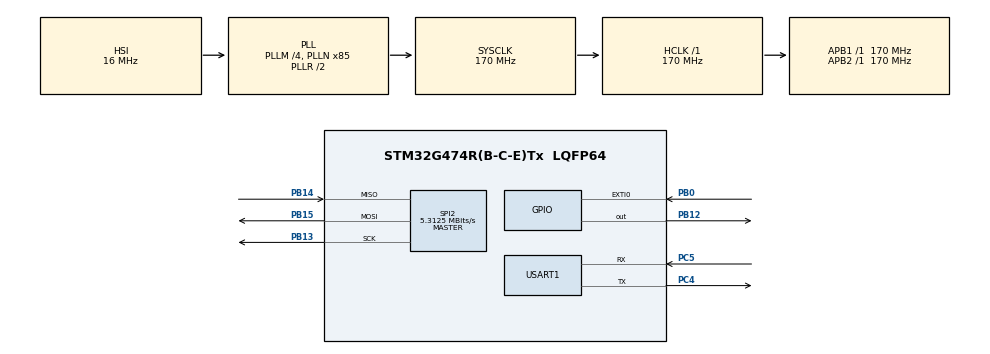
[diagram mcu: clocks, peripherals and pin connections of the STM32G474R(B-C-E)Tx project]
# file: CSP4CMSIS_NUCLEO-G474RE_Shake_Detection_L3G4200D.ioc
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FREERTOS.Tasks01=defaultTask,24,256,StartDefaultTask,Default,NULL,Static,defaultTaskBuffer,defaultTaskControlBlock
FREERTOS.configTOTAL_HEAP_SIZE=1024
FREERTOS.configUSE_NEWLIB_REENTRANT=1
Mcu.Family=STM32G4
Mcu.Name=STM32G474R(B-C-E)Tx
Mcu.Package=LQFP64
NUCLEO-G474RE.BUTTON=1
NUCLEO-G474RE.LD2=true
NUCLEO-G474RE.VCP=true
NVIC.EXTI0_IRQn=true\:5\:0\:false\:false\:true\:true\:true\:true\:true
NVIC.EXTI15_10_IRQn=true\:5\:0\:false\:false\:true\:true\:false\:true\:true
NVIC.PriorityGroup=NVIC_PRIORITYGROUP_4
NVIC.TIM1_UP_TIM16_IRQn=true\:15\:0\:false\:false\:true\:false\:false\:true\:true
NVIC.TimeBase=TIM1_UP_TIM16_IRQn
NVIC.TimeBaseIP=TIM1
PA13.GPIO_Label=T_SWDIO
PA13.Signal=SYS_JTMS-SWDIO
PA14.GPIO_Label=T_SWCLK
PA14.Signal=SYS_JTCK-SWCLK
PA2.Signal=LPUART1_TX
PA3.Signal=LPUART1_RX
PB0.Signal=GPXTI0
PB12.Signal=GPIO_Output
PB13.Mode=Full_Duplex_Master
PB13.Signal=SPI2_SCK
PB14.Mode=Full_Duplex_Master
PB14.Signal=SPI2_MISO
PB15.Mode=Full_Duplex_Master
PB15.Signal=SPI2_MOSI
PB3.GPIO_Label=T_SWO
PB3.Signal=SYS_JTDO-SWO
PC14-OSC32_IN.GPIO_Label=RCC_OSC32_IN
PC14-OSC32_IN.Signal=RCC_OSC32_IN
PC15-OSC32_OUT.GPIO_Label=RCC_OSC32_OUT
PC15-OSC32_OUT.Signal=RCC_OSC32_OUT
PC4.Mode=Asynchronous
PC4.Signal=USART1_TX
PC5.Mode=Asynchronous
PC5.Signal=USART1_RX
PF0-OSC_IN.GPIO_Label=RCC_OSC_IN
PF0-OSC_IN.Signal=RCC_OSC_IN
PF1-OSC_OUT.GPIO_Label=RCC_OSC_OUT
PF1-OSC_OUT.Signal=RCC_OSC_OUT
ProjectManager.HeapSize=0x200
ProjectManager.StackSize=0x400
ProjectManager.TargetToolchain=STM32CubeIDE
RCC.ADC12Freq_Value=170000000
RCC.ADC345Freq_Value=170000000
RCC.AHBFreq_Value=170000000
RCC.APB1Freq_Value=170000000
RCC.APB1TimFreq_Value=170000000
RCC.APB2Freq_Value=170000000
RCC.APB2TimFreq_Value=170000000
RCC.CortexFreq_Value=170000000
RCC.EXTERNAL_CLOCK_VALUE=12288000
RCC.HCLKFreq_Value=170000000
RCC.HSE_VALUE=24000000
RCC.HSI48_VALUE=48000000
RCC.HSI_VALUE=16000000
RCC.LSE_VALUE=32768
RCC.PLLM=RCC_PLLM_DIV4
RCC.PLLN=85
RCC.RTCClockSelection=RCC_RTCCLKSOURCE_LSE
RCC.SYSCLKFreq_VALUE=170000000
RCC.SYSCLKSource=RCC_SYSCLKSOURCE_PLLCLK
RCC.USBFreq_Value=170000000
RCC.VCOOutputFreq_Value=340000000
SPI2.BaudRatePrescaler=SPI_BAUDRATEPRESCALER_32
SPI2.CLKPhase=SPI_PHASE_2EDGE
SPI2.CLKPolarity=SPI_POLARITY_HIGH
SPI2.CalculateBaudRate=5.3125 MBits/s
SPI2.DataSize=SPI_DATASIZE_8BIT
SPI2.Direction=SPI_DIRECTION_2LINES
SPI2.Mode=SPI_MODE_MASTER
SPI2.VirtualType=VM_MASTER
USART1.VirtualMode-Asynchronous=VM_ASYNC
VP_FREERTOS_VS_CMSIS_V2.Mode=CMSIS_V2
VP_NUCLEO-G474RE_VS_BSP_COMMON.Mode=COMMON
VP_SYS_VS_DBSignals.Mode=DisableDeadBatterySignals
VP_SYS_VS_tim1.Mode=TIM1
board=NUCLEO-G474RE

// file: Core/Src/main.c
/* USER CODE BEGIN Header */
/**
  ******************************************************************************
  * @file           : main.c
  * @brief          : Main program body
  ******************************************************************************
  * @attention
  *
  * Copyright (c) 2026 STMicroelectronics.
  * All rights reserved.
  *
  * This software is licensed under terms that can be found in the LICENSE file
  * in the root directory of this software component.
  * If no LICENSE file comes with this software, it is provided AS-IS.
  *
  ******************************************************************************
  */
/* USER CODE END Header */
#include "main.h"
#include "cmsis_os.h"

/* USER CODE BEGIN Includes */
#include "application.h"
#include <stdio.h>
/* USER CODE END Includes */

typedef StaticTask_t osStaticThreadDef_t;

COM_InitTypeDef BspCOMInit;
SPI_HandleTypeDef hspi2;

UART_HandleTypeDef huart1;

void SystemClock_Config(void);
static void MX_GPIO_Init(void);
static void MX_SPI2_Init(void);
static void MX_USART1_UART_Init(void);

int main(void)
{

  /* MCU Configuration--------------------------------------------------------*/

  /* Reset of all peripherals, Initializes the Flash interface and the Systick. */
  HAL_Init();

  /* Configure the system clock */
  SystemClock_Config();

  /* Initialize all configured peripherals */
  MX_GPIO_Init();
  MX_SPI2_Init();
  MX_USART1_UART_Init();
  /* USER CODE BEGIN 2 */
  /* Unbuffered stdout: newlib's printf() would otherwise malloc() a 1 KB stdout buffer on first
     use (measured: 1032 B). With this, nothing in the program allocates heap memory. */
  setvbuf(stdout, NULL, _IONBF, 0);

  /* USER CODE END 2 */

  /* Init scheduler */
  osKernelInitialize();

  /* USER CODE BEGIN RTOS_THREADS */
  /* add threads, ... */
  csp_app_main_init();  /* application.cpp: creates MainApp, which starts the CSP network */
  /* USER CODE END RTOS_THREADS */

  /* Initialize led */
  BSP_LED_Init(LED_GREEN);

  /* Initialize USER push-button, will be used to trigger an interrupt each time it's pressed.*/
  BSP_PB_Init(BUTTON_USER, BUTTON_MODE_EXTI);

  /* Initialize COM1 port (115200, 8 bits (7-bit data + 1 stop bit), no parity */
  BspCOMInit.BaudRate   = 115200;
  BspCOMInit.WordLength = COM_WORDLENGTH_8B;
  BspCOMInit.StopBits   = COM_STOPBITS_1;
  BspCOMInit.Parity     = COM_PARITY_NONE;
  BspCOMInit.HwFlowCtl  = COM_HWCONTROL_NONE;
  if (BSP_COM_Init(COM1, &BspCOMInit) != BSP_ERROR_NONE)
  {
    Error_Handler();
  }

  /* Start scheduler */
  osKernelStart();

  /* We should never get here as control is now taken by the scheduler */

  /* Infinite loop */
  while (1)
  {

  }
}

void SystemClock_Config(void)
{
  RCC_OscInitTypeDef RCC_OscInitStruct = {0};
  RCC_ClkInitTypeDef RCC_ClkInitStruct = {0};

  /** Configure the main internal regulator output voltage
  */
  HAL_PWREx_ControlVoltageScaling(PWR_REGULATOR_VOLTAGE_SCALE1_BOOST);

  /** Initializes the RCC Oscillators according to the specified parameters
  * in the RCC_OscInitTypeDef structure.
  */
  RCC_OscInitStruct.OscillatorType = RCC_OSCILLATORTYPE_HSI;
  RCC_OscInitStruct.HSIState = RCC_HSI_ON;
  RCC_OscInitStruct.HSICalibrationValue = RCC_HSICALIBRATION_DEFAULT;
  RCC_OscInitStruct.PLL.PLLState = RCC_PLL_ON;
  RCC_OscInitStruct.PLL.PLLSource = RCC_PLLSOURCE_HSI;
  RCC_OscInitStruct.PLL.PLLM = RCC_PLLM_DIV4;
  RCC_OscInitStruct.PLL.PLLN = 85;
  RCC_OscInitStruct.PLL.PLLP = RCC_PLLP_DIV2;
  RCC_OscInitStruct.PLL.PLLQ = RCC_PLLQ_DIV2;
  RCC_OscInitStruct.PLL.PLLR = RCC_PLLR_DIV2;
  if (HAL_RCC_OscConfig(&RCC_OscInitStruct) != HAL_OK)
  {
    Error_Handler();
  }

  /** Initializes the CPU, AHB and APB buses clocks
  */
  RCC_ClkInitStruct.ClockType = RCC_CLOCKTYPE_HCLK|RCC_CLOCKTYPE_SYSCLK
                              |RCC_CLOCKTYPE_PCLK1|RCC_CLOCKTYPE_PCLK2;
  RCC_ClkInitStruct.SYSCLKSource = RCC_SYSCLKSOURCE_PLLCLK;
  RCC_ClkInitStruct.AHBCLKDivider = RCC_SYSCLK_DIV1;
  RCC_ClkInitStruct.APB1CLKDivider = RCC_HCLK_DIV1;
  RCC_ClkInitStruct.APB2CLKDivider = RCC_HCLK_DIV1;

  if (HAL_RCC_ClockConfig(&RCC_ClkInitStruct, FLASH_LATENCY_4) != HAL_OK)
  {
    Error_Handler();
  }
}

static void MX_SPI2_Init(void)
{

  /* SPI2 parameter configuration*/
  hspi2.Instance = SPI2;
  hspi2.Init.Mode = SPI_MODE_MASTER;
  hspi2.Init.Direction = SPI_DIRECTION_2LINES;
  hspi2.Init.DataSize = SPI_DATASIZE_8BIT;
  hspi2.Init.CLKPolarity = SPI_POLARITY_HIGH;
  hspi2.Init.CLKPhase = SPI_PHASE_2EDGE;
  hspi2.Init.NSS = SPI_NSS_SOFT;
  hspi2.Init.BaudRatePrescaler = SPI_BAUDRATEPRESCALER_32;
  hspi2.Init.FirstBit = SPI_FIRSTBIT_MSB;
  hspi2.Init.TIMode = SPI_TIMODE_DISABLE;
  hspi2.Init.CRCCalculation = SPI_CRCCALCULATION_DISABLE;
  hspi2.Init.CRCPolynomial = 7;
  hspi2.Init.CRCLength = SPI_CRC_LENGTH_DATASIZE;
  hspi2.Init.NSSPMode = SPI_NSS_PULSE_DISABLE;
  if (HAL_SPI_Init(&hspi2) != HAL_OK)
  {
    Error_Handler();
  }

}

static void MX_USART1_UART_Init(void)
{

  huart1.Instance = USART1;
  huart1.Init.BaudRate = 115200;
  huart1.Init.WordLength = UART_WORDLENGTH_8B;
  huart1.Init.StopBits = UART_STOPBITS_1;
  huart1.Init.Parity = UART_PARITY_NONE;
  huart1.Init.Mode = UART_MODE_TX_RX;
  huart1.Init.HwFlowCtl = UART_HWCONTROL_NONE;
  huart1.Init.OverSampling = UART_OVERSAMPLING_16;
  huart1.Init.OneBitSampling = UART_ONE_BIT_SAMPLE_DISABLE;
  huart1.Init.ClockPrescaler = UART_PRESCALER_DIV1;
  huart1.AdvancedInit.AdvFeatureInit = UART_ADVFEATURE_NO_INIT;
  if (HAL_UART_Init(&huart1) != HAL_OK)
  {
    Error_Handler();
  }
  if (HAL_UARTEx_SetTxFifoThreshold(&huart1, UART_TXFIFO_THRESHOLD_1_8) != HAL_OK)
  {
    Error_Handler();
  }
  if (HAL_UARTEx_SetRxFifoThreshold(&huart1, UART_RXFIFO_THRESHOLD_1_8) != HAL_OK)
  {
    Error_Handler();
  }
  if (HAL_UARTEx_DisableFifoMode(&huart1) != HAL_OK)
  {
    Error_Handler();
  }

}

static void MX_GPIO_Init(void)
{
  GPIO_InitTypeDef GPIO_InitStruct = {0};

  /* GPIO Ports Clock Enable */
  __HAL_RCC_GPIOC_CLK_ENABLE();
  __HAL_RCC_GPIOF_CLK_ENABLE();
  __HAL_RCC_GPIOB_CLK_ENABLE();
  __HAL_RCC_GPIOA_CLK_ENABLE();

  /*Configure GPIO pin Output Level */
  HAL_GPIO_WritePin(GPIOB, GPIO_PIN_12, GPIO_PIN_RESET);

  /*Configure GPIO pin : PB0 */
  GPIO_InitStruct.Pin = GPIO_PIN_0;
  GPIO_InitStruct.Mode = GPIO_MODE_IT_RISING;
  GPIO_InitStruct.Pull = GPIO_NOPULL;
  HAL_GPIO_Init(GPIOB, &GPIO_InitStruct);

  /*Configure GPIO pin : PB12 */
  GPIO_InitStruct.Pin = GPIO_PIN_12;
  GPIO_InitStruct.Mode = GPIO_MODE_OUTPUT_PP;
  GPIO_InitStruct.Pull = GPIO_NOPULL;
  GPIO_InitStruct.Speed = GPIO_SPEED_FREQ_LOW;
  HAL_GPIO_Init(GPIOB, &GPIO_InitStruct);

  /* EXTI interrupt init*/
  HAL_NVIC_SetPriority(EXTI0_IRQn, 5, 0);
  HAL_NVIC_EnableIRQ(EXTI0_IRQn);

}

/* USER CODE BEGIN 4 */
void vAssertCalled(const char *file, int line)
{
  taskDISABLE_INTERRUPTS();
  printf("\r\nconfigASSERT failed: %s:%d\r\n", file, line);
  for (;;) { }
}
/* USER CODE END 4 */

void HAL_TIM_PeriodElapsedCallback(TIM_HandleTypeDef *htim)
{
  if (htim->Instance == TIM1)
  {
    HAL_IncTick();
  }
}

void Error_Handler(void)
{
  __disable_irq();
  while (1)
  {
  }
}
